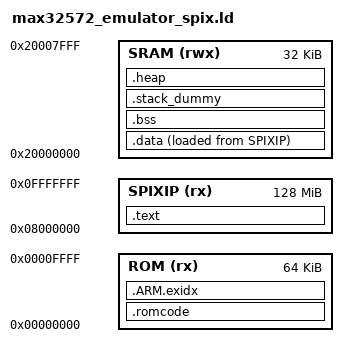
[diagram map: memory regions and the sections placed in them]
/******************************************************************************
 *
 * Copyright (C) 2022-2023 Maxim Integrated Products, Inc. (now owned by 
 * Analog Devices, Inc.),
 * Copyright (C) 2023-2024 Analog Devices, Inc.
 *
 * Licensed under the Apache License, Version 2.0 (the "License");
 * you may not use this file except in compliance with the License.
 * You may obtain a copy of the License at
 *
 *     http://www.apache.org/licenses/LICENSE-2.0
 *
 * Except as contained in this notice, the name of Maxim Integrated
 * Products, Inc. shall not be used except as stated in the Maxim Integrated
 * Products, Inc. Branding Policy.
 *
 * The mere transfer of this software does not imply any licenses
 * of trade secrets, proprietary technology, copyrights, patents,
 * trademarks, maskwork rights, or any other form of intellectual
 * property whatsoever. Maxim Integrated Products, Inc. retains all
 * ownership rights.
 *
 * $Date: 2018-12-18 15:37:22 -0600 (Tue, 18 Dec 2018) $ 
 * $Revision: 40072 $
 *
 ******************************************************************************/

MEMORY {
    ROM (rx) : ORIGIN = 0x00000000, LENGTH = 64K
    SPIXIP (rx) : ORIGIN = 0x08000000, LENGTH = 128M
    /*SRAM (rwx) : ORIGIN = 0x20000000, LENGTH = 432K*/
    SRAM (rwx) : ORIGIN = 0x20000000, LENGTH = 0x00008000 /*32kB SRAM0 */
    /*SRAM (rwx) : ORIGIN = 0x20000000, LENGTH = 0x00048000 /* 288kB SRAM, leaving last 32kB for openocd work area */
}

SECTIONS {

    .romcode :
    {
        //_text = .;
        KEEP(*(.isr_vector))
        KEEP(*(.Reset))
        
        KEEP(*(.init))
        KEEP(*(.fini))

        /* C++ Exception handling */
        KEEP(*(.eh_frame*))
        //_etext = .;
    } > ROM
    
    .text :
    {
        _text = .;
        *(.text*)    /* program code */
        *(.rodata*)  /* read-only data: "const" */
        _etext = .;
    } > SPIXIP
    
    /* it's used for C++ exception handling      */
    /* we need to keep this to avoid overlapping */
    .ARM.exidx :
    {
        __exidx_start = .;
        *(.ARM.exidx*)
        __exidx_end = .;
    } > ROM

    .data :
    {
        _data = ALIGN(., 4);
        *(.data*)           /*read-write initialized data: initialized global variable*/
        KEEP(*(.spix_config*))    /* SPIX configuration functions need to be run from SRAM */

        /* These array sections are used by __libc_init_array to call static C++ constructors */
        . = ALIGN(4);
        /* preinit data */
        PROVIDE_HIDDEN (__preinit_array_start = .);
        KEEP(*(.preinit_array))
        PROVIDE_HIDDEN (__preinit_array_end = .);

        . = ALIGN(4);
        /* init data */
        PROVIDE_HIDDEN (__init_array_start = .);
        KEEP(*(SORT(.init_array.*)))
        KEEP(*(.init_array))
        PROVIDE_HIDDEN (__init_array_end = .);

        . = ALIGN(4);
        /* finit data */
        PROVIDE_HIDDEN (__fini_array_start = .);
        KEEP(*(SORT(.fini_array.*)))
        KEEP(*(.fini_array))
        PROVIDE_HIDDEN (__fini_array_end = .);

        _edata = ALIGN(., 4);
    } > SRAM AT>SPIXIP
    __load_data = LOADADDR(.data);

    .bss :
    {
        . = ALIGN(4);
        _bss = .;
        *(.bss*)     /*read-write zero initialized data: uninitialzed global variable*/
        *(COMMON)
        _ebss = ALIGN(., 4);
    } > SRAM

    /* Set stack top to end of RAM, and stack limit move down by
     * size of stack_dummy section */
    __StackTop = ORIGIN(SRAM) + LENGTH(SRAM);
    __StackLimit = __StackTop - SIZEOF(.stack_dummy);

    /* .stack_dummy section doesn't contains any symbols. It is only
     * used for linker to calculate size of stack sections, and assign
     * values to stack symbols later */
    .stack_dummy (COPY):
    {
        *(.stack*)
    } > SRAM

    .heap (COPY):
    {
        . = ALIGN(4);
        *(.heap*)
        __HeapLimit = ABSOLUTE(__StackLimit);
    } > SRAM

    PROVIDE(__stack = __StackTop);

    /* Check if data + heap + stack exceeds RAM limit */
    ASSERT(__StackLimit >= _ebss, "region RAM overflowed with stack")
}
